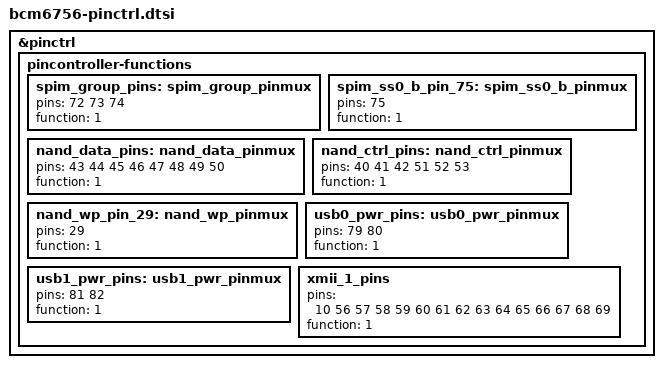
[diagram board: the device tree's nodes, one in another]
&pinctrl {
	pincontroller-functions {
		spim_group_pins: spim_group_pinmux {
			pins = <72 73 74>;
			function = <1>;
		};

		spim_ss0_b_pin_75: spim_ss0_b_pinmux {
			pins = <75>;
			function = <1>;
		};

		nand_data_pins: nand_data_pinmux {
			pins = <43 44 45 46 47 48 49 50>;
			function = <1>;
		};

		nand_ctrl_pins: nand_ctrl_pinmux {
			pins = <40 41 42 51 52 53>;
			function = <1>;
		};
		nand_wp_pin_29: nand_wp_pinmux {
			pins = <29>;
			function = <1>;
		};

		usb0_pwr_pins: usb0_pwr_pinmux {
			pins = <79 80>;
			function = <1>;
		};

		usb1_pwr_pins: usb1_pwr_pinmux {
			pins = <81 82>;
			function = <1>;
		};

		xmii_1_pins: xmii_1_pins {
			pins = <10 56 57 58 59 60 61 62 63 64 65 66 67 68 69>;
			function = <1>;
		};
	};
};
